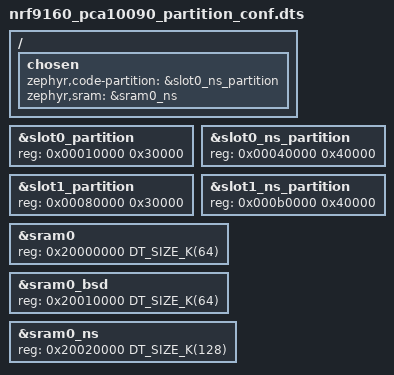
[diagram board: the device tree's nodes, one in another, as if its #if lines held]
/*
 * Copyright (c) 2018 Nordic Semiconductor ASA
 *
 * SPDX-License-Identifier: Apache-2.0
 */

#if defined(CONFIG_ARM_TRUSTZONE_M)

/*
 * Zephyr build with TrustZone-M support, implies building
 * Secure and Non-Secure images.
 * - Secure image will be placed in slot0, and use sram0
 *   for system memory.
 * - Non-Secure image will be placed in slot0_ns, and use
 *   sram0_ns for system memory.
 *
 * Depending on whether MCUboot is present, slot0 will start
 * - from address 0x00000000 (MCUboot not present),
 * - from address 0x00010000 (MCUboot present).
 */

&slot0_partition {
#if defined (CONFIG_BOOTLOADER_MCUBOOT)
	reg = <0x00010000 0x30000>;
#else
	reg = <0x00000000 0x30000>;
#endif
};

&slot0_ns_partition {
	reg = <0x00040000 0x40000>;
};

&slot1_partition {
	reg = <0x00080000 0x30000>;
};

&slot1_ns_partition {
	reg = <0x000b0000 0x40000>;
};

/* SRAM planning when building with TrustZone-M support
 * - Lowest 64 kB SRAM allocated to Secure image (sram0).
 * - 64 kB SRAM reserved for and used by the BSD socket
 *   library.
 * - Upper 128 kB allocated to Non-Secure image (sram0_ns).
 */

&sram0 {
	reg = <0x20000000 DT_SIZE_K(64)>;
};

&sram0_bsd {
	reg = <0x20010000 DT_SIZE_K(64)>;
};

&sram0_ns {
	reg = <0x20020000 DT_SIZE_K(128)>;
};

#if defined(CONFIG_ARM_SECURE_FIRMWARE)
/ {
	chosen {
		zephyr,code-partition = &slot0_partition;
		zephyr,sram = &sram0;
	};
};
#endif

#if defined (CONFIG_ARM_NONSECURE_FIRMWARE)
/ {
	chosen {
		zephyr,code-partition = &slot0_ns_partition;
		zephyr,sram = &sram0_ns;
	};
};
#endif

#else /* CONFIG_ARM_TRUSTZONE_M */
/*
 * Zephyr build without TrustZone-M support.
 * Image placement is determined by whether
 * MCUboot is present or not (image placement
 * determined with help of MCUboot.overlay).
 */
&slot0_partition {
	reg = <0x00010000 0x70000>;
};

&slot1_partition {
	reg = <0x00080000 0x70000>;
};

/* Lowest 64K SRAM reserved for and used
 * by the BSD socket library.
 */
&sram0_bsd {
	reg = <0x20000000 DT_SIZE_K(64)>;
};

&sram0 {
	reg = <0x20010000 DT_SIZE_K(192)>;
};

#endif /* CONFIG_ARM_TRUSTZONE_M */
